# STM32WB55 register map
File version: 2.0
CPU: CM4 r0p1, little endian, MPU, FPU, 4 interrupt priority bits
Registers are 32-bit, read-write, reset 0x0 unless marked. A register's access mark holds for its fields unless they carry their own. Offsets are from the block's base; [hi:lo] are bit positions; {n}, {i} and the like mark numbered series; 'fields as' and 'values as' point back to an identical list.

## EXTI — External interrupt/event controller
Base 0x58000800
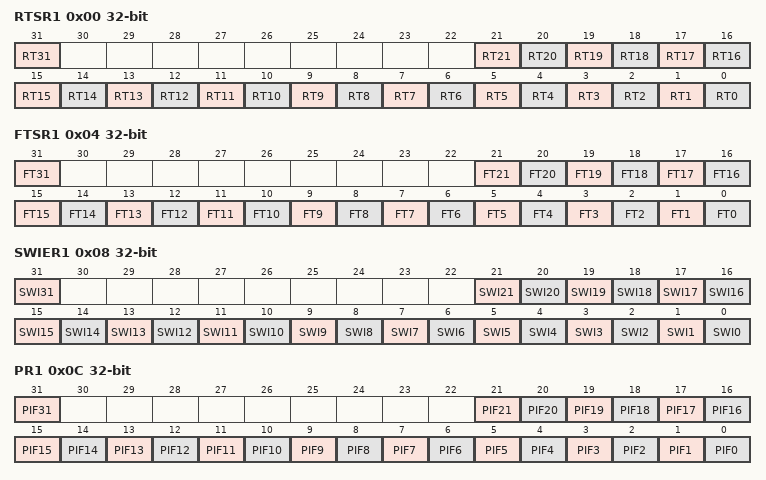
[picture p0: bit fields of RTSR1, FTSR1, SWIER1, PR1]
0x00 RTSR1 — rising trigger selection register
  [31] RT31 — Rising trigger event configuration bit of Configurable Event input
  [n] RT{n} (n=0..21) — Rising trigger event configuration bit of Configurable Event input
0x04 FTSR1 — falling trigger selection register
  [31] FT31 — Falling trigger event configuration bit of Configurable Event input
  [n] FT{n} (n=0..21) — Falling trigger event configuration bit of Configurable Event input
0x08 SWIER1 — software interrupt event register
  [31] SWI31 — Software interrupt on event
  [n] SWI{n} (n=0..21) — Software interrupt on event
0x0C PR1 — EXTI pending register
  [31] PIF31 — Configurable event inputs Pending bit
  [n] PIF{n} (n=0..21) — Configurable event inputs Pending bit
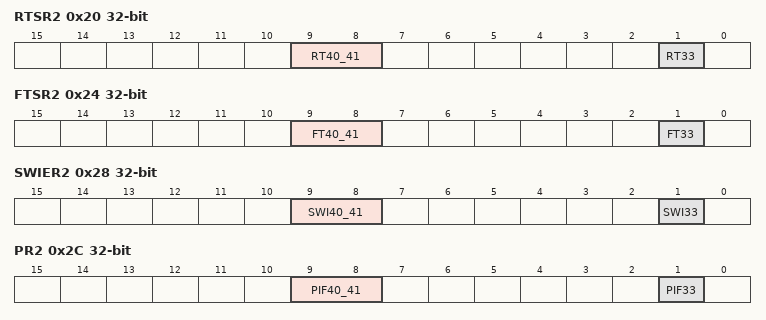
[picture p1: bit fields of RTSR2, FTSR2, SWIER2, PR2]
0x20 RTSR2 — rising trigger selection register
  [9:8] RT40_41 — Rising trigger event configuration bit of Configurable Event input
  [1] RT33 — Rising trigger event configuration bit of Configurable Event input
0x24 FTSR2 — falling trigger selection register
  [9:8] FT40_41 — Falling trigger event configuration bit of Configurable Event input
  [1] FT33 — Falling trigger event configuration bit of Configurable Event input
0x28 SWIER2 — software interrupt event register
  [9:8] SWI40_41 — Software interrupt on event
  [1] SWI33 — Software interrupt on event
0x2C PR2 — pending register
  [9:8] PIF40_41 — Configurable event inputs x+32 Pending bit.
  [1] PIF33 — Configurable event inputs x+32 Pending bit.
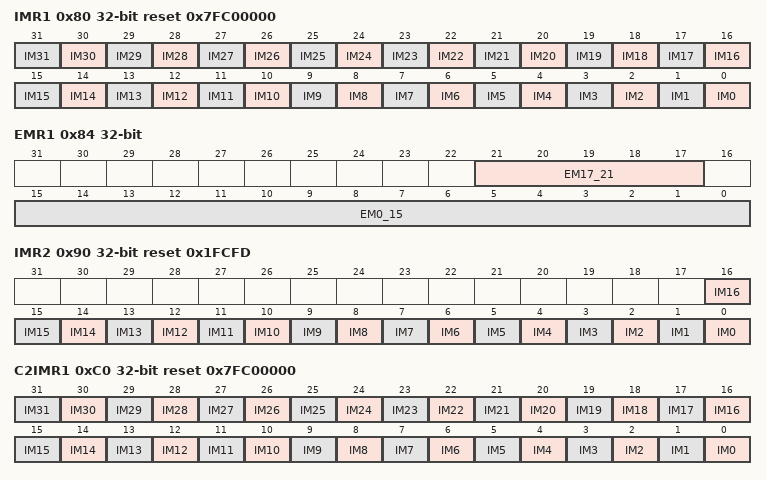
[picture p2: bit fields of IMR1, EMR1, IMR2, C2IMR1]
0x80 IMR1 reset 0x7FC00000 — CPUm wakeup with interrupt mask register
  [n] IM{n} (n=0..31) — CPU(m) wakeup with interrupt Mask on Event input
0x84 EMR1 — CPUm wakeup with event mask register
  [21:17] EM17_21 — CPU(m) Wakeup with event generation Mask on Event input
  [15:0] EM0_15 — CPU(m) Wakeup with event generation Mask on Event input
0x90 IMR2 reset 0x1FCFD — CPUm wakeup with interrupt mask register
  [n] IM{n} (n=0..16) — CPUm Wakeup with interrupt Mask on Event input
0x94 EMR2 — CPUm wakeup with event mask register
  [9:8] EM — CPU(m) Wakeup with event generation Mask on Event input
0xC0 C2IMR1 reset 0x7FC00000 — CPUm wakeup with interrupt mask register
  fields as IMR1
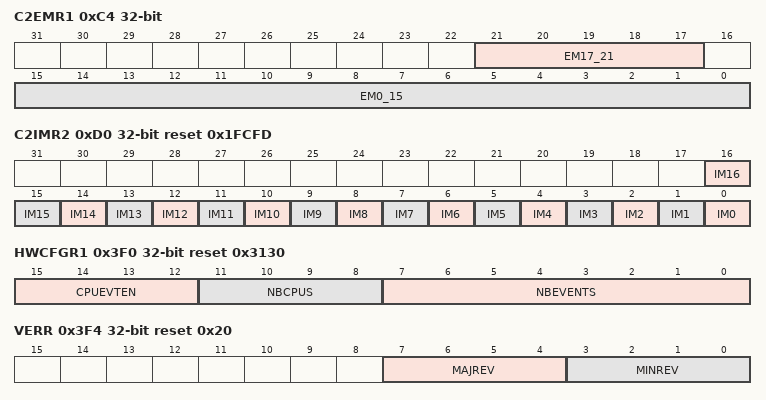
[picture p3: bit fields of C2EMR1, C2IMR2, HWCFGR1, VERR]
0xC4 C2EMR1 — CPUm wakeup with event mask register
  fields as EMR1
0xD0 C2IMR2 reset 0x1FCFD — CPUm wakeup with interrupt mask register
  [n] IM{n} (n=0..16) — CPUm Wakeup with interrupt Mask on Event input
0xD4 C2EMR2 — CPUm wakeup with event mask register
  [9:8] EM — CPU(m) Wakeup with event generation Mask on Event input
0x3D8 HWCFGR7 ro — EXTI Hardware configuration registers
  [31:0] CPUEVENT — HW configuration CPU event generation
0x3DC HWCFGR6 ro reset 0x300 — Hardware configuration registers
  [31:0] CPUEVENT — HW configuration CPU event generation
0x3E0 HWCFGR5 ro reset 0x3EFFFF — Hardware configuration registers
  [31:0] CPUEVENT — HW configuration CPU event generation
0x3E4 HWCFGR4 ro — Hardware configuration registers
  [31:0] EVENT_TRG — HW configuration event trigger type
0x3E8 HWCFGR3 ro reset 0x302 — Hardware configuration registers
  [31:0] EVENT_TRG — HW configuration event trigger type
0x3EC HWCFGR2 ro reset 0x803FFFFF — Hardware configuration registers
  [31:0] EVENT_TRG — HW configuration event trigger type
0x3F0 HWCFGR1 ro reset 0x3130 — Hardware configuration register 1
  [15:12] CPUEVTEN — HW configuration of CPU(m) event output enable
  [11:8] NBCPUS — HW configuration number of CPUs
  [7:0] NBEVENTS — HW configuration number of event
0x3F4 VERR ro reset 0x20 — EXTI IP Version register
  [7:4] MAJREV — Major Revision number
  [3:0] MINREV — Minor Revision number
0x3F8 IPIDR ro reset 0xE0001 — Identification register
  [31:0] IPID — IP Identification
0x3FC SIDR ro reset 0xA3C5DD01 — Size ID register
  [31:0] SID — Size Identification
